# TREMO register map
File version: 1.6.2
CPU: CM4 r0p1, little endian, MPU, FPU, 3 interrupt priority bits
Registers are 32-bit, read-write, reset 0x0 unless marked. A register's access mark holds for its fields unless they carry their own. Offsets are from the block's base; [hi:lo] are bit positions; 'fields as' and 'values as' point back to an identical list.

## LPTIMER0 — LPTIMER
Base 0x4000D000
Same registers: LPTIMER1 0x4000D800
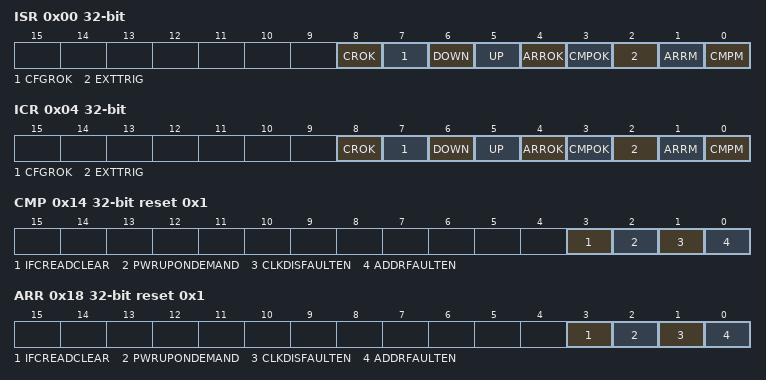
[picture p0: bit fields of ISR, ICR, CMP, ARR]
0x00 ISR ro — LPTIMER flag and status register
  [8] CROK — CR register register operation status
  [7] CFGROK — CFGR register operation status
  [6] DOWN — Counter direction change up to down
  [5] UP — Counter direction change down to up
  [4] ARROK — Autoreload register update OK
  [3] CMPOK — Compare register update OK
  [2] EXTTRIG — External trigger edge event
  [1] ARRM — Autoreload match
  [0] CMPM — Compare match
0x04 ICR wo — LPTIMER flag clear register
  fields as ISR
0x08 IER reset 0x1 — LPTIMER interrupt enable register
  [0] ADDRFAULTEN — Invalid Address Bus Fault Response Enable
0x0C CFGR reset 0x1 — LPTIMER configuration register
  [0] ADDRFAULTEN — Invalid Address Bus Fault Response Enable
0x10 CR reset 0x1 — LPTIMER control register
  [0] ADDRFAULTEN — Invalid Address Bus Fault Response Enable
0x14 CMP reset 0x1 — LPTIMER compare register
  [3] IFCREADCLEAR — IFC Read Clears IF
  [2] PWRUPONDEMAND — Power Up on Demand During Wake Up
  [1] CLKDISFAULTEN — Clock-disabled Bus Fault Response Enable
  [0] ADDRFAULTEN — Invalid Address Bus Fault Response Enable
0x18 ARR reset 0x1 — LPTIMER autoreload register
  fields as CMP
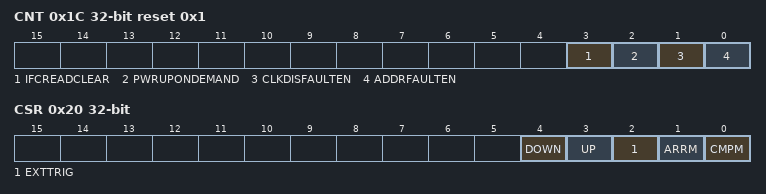
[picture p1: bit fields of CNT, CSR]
0x1C CNT ro reset 0x1 — LPTIMER counter register
  [3] IFCREADCLEAR rw — IFC Read Clears IF
  [2] PWRUPONDEMAND rw — Power Up on Demand During Wake Up
  [1] CLKDISFAULTEN rw — Clock-disabled Bus Fault Response Enable
  [0] ADDRFAULTEN rw — Invalid Address Bus Fault Response Enable
0x20 CSR ro — LPTIMER CSR register
  [4] DOWN — Counter direction change up to down
  [3] UP — Counter direction change down to up
  [2] EXTTRIG — External trigger edge event
  [1] ARRM — Autoreload match
  [0] CMPM — Compare match
0x24 SR1 ro reset 0x1 — LPTIMER SR1 register
  [0] ADDRFAULTEN rw — Invalid Address Bus Fault Response Enable

## I2S
Base 0x40002000
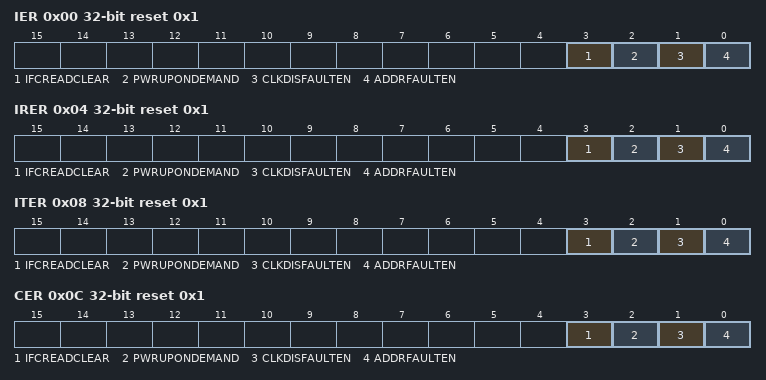
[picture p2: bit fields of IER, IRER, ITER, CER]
0x00 IER reset 0x1 — enable register
  [3] IFCREADCLEAR — IFC Read Clears IF
  [2] PWRUPONDEMAND — Power Up on Demand During Wake Up
  [1] CLKDISFAULTEN — Clock-disabled Bus Fault Response Enable
  [0] ADDRFAULTEN — Invalid Address Bus Fault Response Enable
0x04 IRER reset 0x1 — receiver block enable register
  fields as IER
0x08 ITER reset 0x1 — transmitter block enable register
  fields as IER
0x0C CER reset 0x1 — clock enable register
  fields as IER
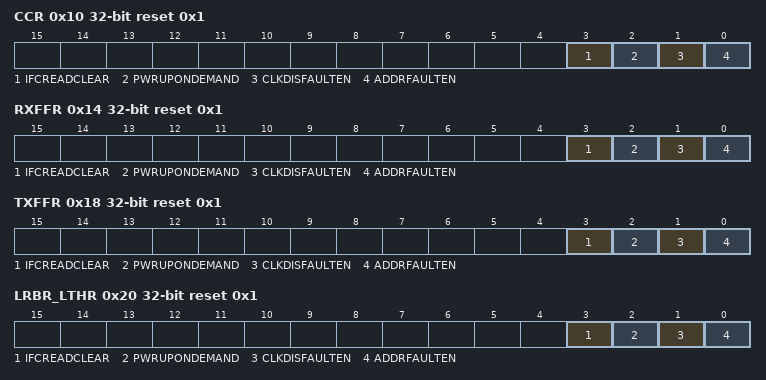
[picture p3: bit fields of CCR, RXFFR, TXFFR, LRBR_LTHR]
0x10 CCR reset 0x1 — clock configuration register
  fields as IER
0x14 RXFFR wo reset 0x1 — receiver block FIFO reset register
  [3] IFCREADCLEAR rw — IFC Read Clears IF
  [2] PWRUPONDEMAND rw — Power Up on Demand During Wake Up
  [1] CLKDISFAULTEN rw — Clock-disabled Bus Fault Response Enable
  [0] ADDRFAULTEN rw — Invalid Address Bus Fault Response Enable
0x18 TXFFR wo reset 0x1 — transmitter block FIFO reset register
  fields as RXFFR
0x20 LRBR_LTHR reset 0x1 — right receive buffer register
  fields as IER
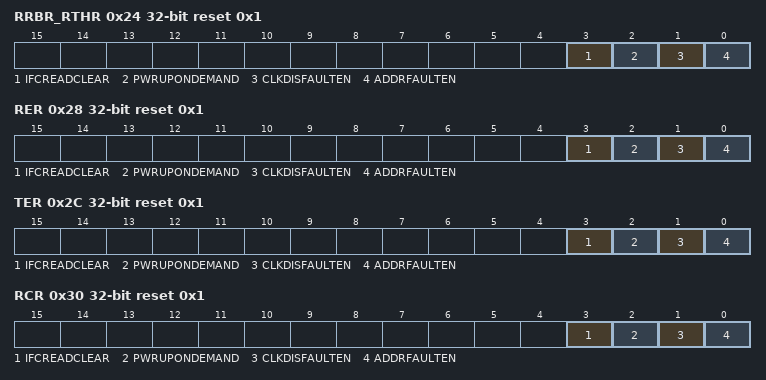
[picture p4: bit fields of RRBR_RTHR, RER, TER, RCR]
0x24 RRBR_RTHR reset 0x1 — right transmit holding register
  fields as IER
0x28 RER reset 0x1 — receiver enable register
  fields as IER
0x2C TER reset 0x1 — transmitter enable register
  fields as IER
0x30 RCR reset 0x1 — receiver configuration register
  fields as IER
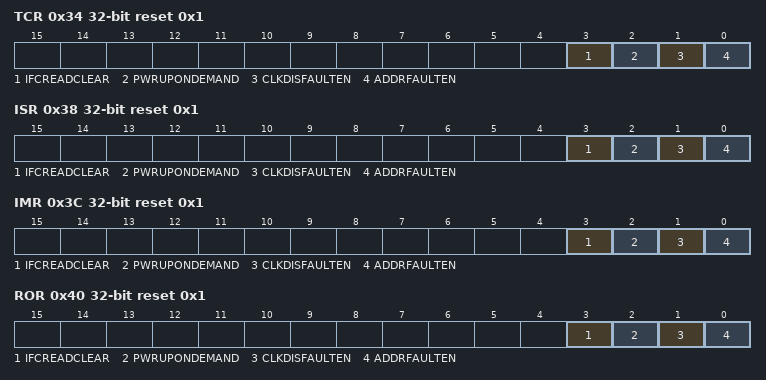
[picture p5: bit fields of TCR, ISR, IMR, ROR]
0x34 TCR reset 0x1 — transmitter configuration register
  fields as IER
0x38 ISR ro reset 0x1 — interrupt status register
  fields as RXFFR
0x3C IMR reset 0x1 — interrupt mask register
  fields as IER
0x40 ROR ro reset 0x1 — receiver overrun register
  fields as RXFFR
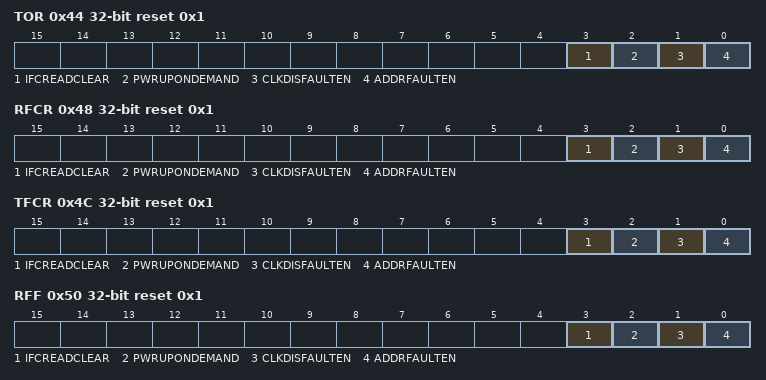
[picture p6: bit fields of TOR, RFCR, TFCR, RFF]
0x44 TOR ro reset 0x1 — transmitter overrun register
  fields as RXFFR
0x48 RFCR reset 0x1 — receiver FIFO configuration register
  fields as IER
0x4C TFCR reset 0x1 — transmitter FIFO configuration register
  fields as IER
0x50 RFF wo reset 0x1 — receiver FIFO flush register
  fields as RXFFR
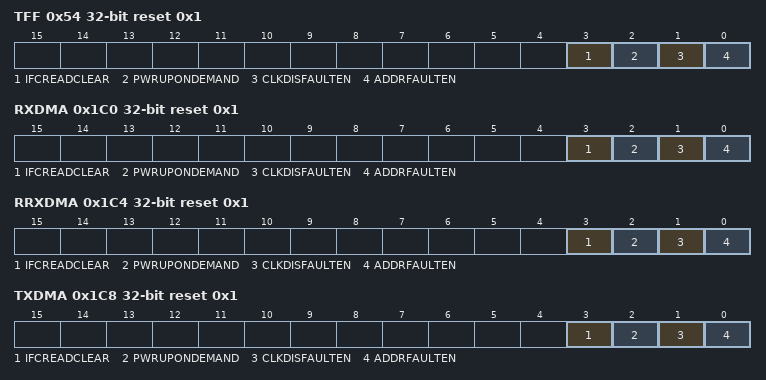
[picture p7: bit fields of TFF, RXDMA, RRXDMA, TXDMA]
0x54 TFF wo reset 0x1 — transmitter FIFO flush register
  fields as RXFFR
0x1C0 RXDMA reset 0x1 — receiver block dma register
  fields as IER
0x1C4 RRXDMA wo reset 0x1 — reset receiver block dma register
  fields as RXFFR
0x1C8 TXDMA reset 0x1 — transmitter block dma register
  fields as IER
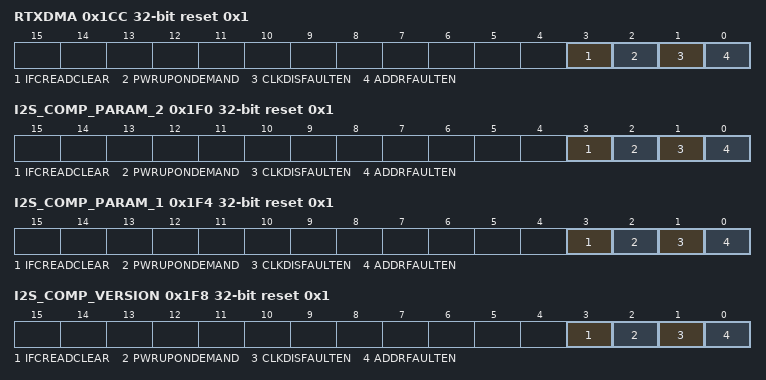
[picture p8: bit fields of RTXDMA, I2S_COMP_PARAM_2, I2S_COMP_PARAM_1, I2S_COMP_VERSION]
0x1CC RTXDMA wo reset 0x1 — reset transmitter block dma register
  fields as RXFFR
0x1F0 I2S_COMP_PARAM_2 ro reset 0x1 — component parameter register 2
  fields as RXFFR
0x1F4 I2S_COMP_PARAM_1 ro reset 0x1 — component parameter register 1
  fields as RXFFR
0x1F8 I2S_COMP_VERSION ro reset 0x1 — component version register
  fields as RXFFR
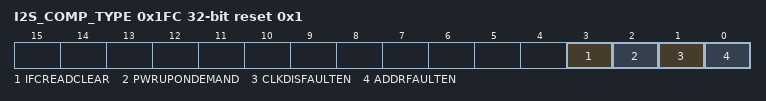
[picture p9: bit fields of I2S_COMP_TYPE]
0x1FC I2S_COMP_TYPE ro reset 0x1 — component type register
  fields as RXFFR
